# STM32L412C8T6 register map
File version: 1.0
Registers are 32-bit, access not given, reset 0x0 unless marked. A register's access mark holds for its fields unless they carry their own. Offsets are from the block's base; [hi:lo] are bit positions; {n}, {i} and the like mark numbered series; 'fields as' and 'values as' point back to an identical list.

## SDMMC
Base 0x40012800
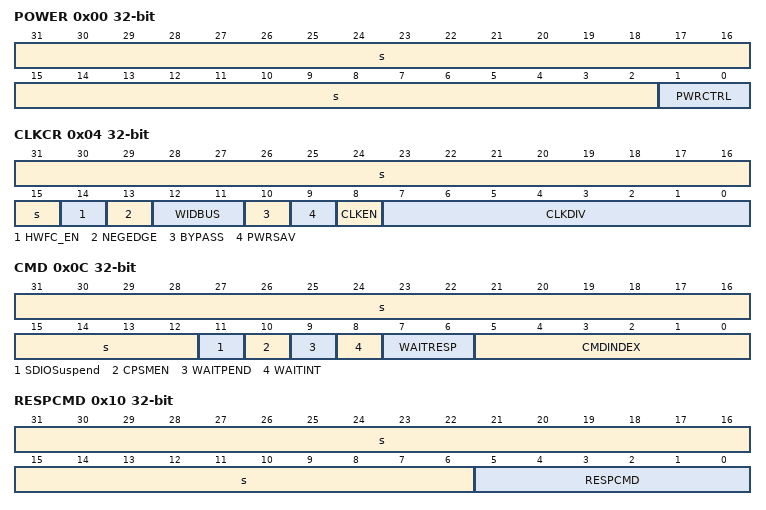
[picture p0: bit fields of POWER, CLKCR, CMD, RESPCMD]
0x00 POWER
  [31:2] s, [1:0] PWRCTRL
0x04 CLKCR
  [31:15] s, [14] HWFC_EN, [13] NEGEDGE, [12:11] WIDBUS, [10] BYPASS, [9] PWRSAV, [8] CLKEN, [7:0] CLKDIV
0x08 ARG
  [31:0] CMDARG
0x0C CMD
  [31:12] s, [11] SDIOSuspend, [10] CPSMEN, [9] WAITPEND, [8] WAITINT, [7:6] WAITRESP, [5:0] CMDINDEX
0x10 RESPCMD
  [31:6] s, [5:0] RESPCMD
{0x10+4i} RESP{i} (i=1..4)
  [31:0] CARDSTATUS{i}
0x24 DTIMER
  [31:0] DATATIME
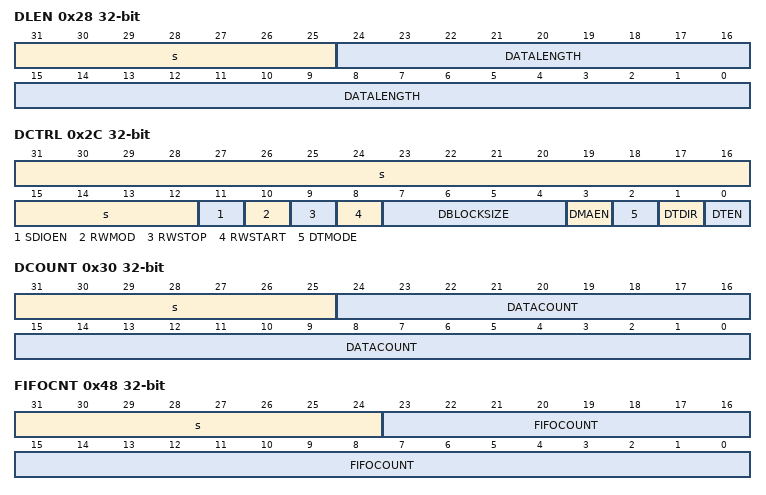
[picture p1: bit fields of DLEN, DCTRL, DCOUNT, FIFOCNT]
0x28 DLEN
  [31:25] s, [24:0] DATALENGTH
0x2C DCTRL
  [31:12] s, [11] SDIOEN, [10] RWMOD, [9] RWSTOP, [8] RWSTART, [7:4] DBLOCKSIZE, [3] DMAEN, [2] DTMODE, [1] DTDIR, [0] DTEN
0x30 DCOUNT
  [31:25] s, [24:0] DATACOUNT
0x34 STA
  [22] SDIOIT, [21] RXDAVL, [20] TXDAVL, [19] RXFIFOE, [18] TXFIFOE, [17] RXFIFOF, [16] TXFIFOF, [15] RXFIFOHF, [14] TXFIFOHE, [13] RXACT, [12] TXACT, [11] CMDACT, [10] DBCKEND, [31:9] s, [8] DATAEND, [7] CMDSENT, [6] CMDREND, [5] RXOVERR, [4] TXUNDERR, [3] DTIMEOUT, [2] CTIMEOUT, [1] DCRCFAIL, [0] CCRCFAIL
0x38 ICR
  [22] SDIOITC, [10] DBCKENDC, [31:9] s, [8] DATAENDC, [7] CMDSENTC, [6] CMDRENDC, [5] RXOVERRC, [4] TXUNDERRC, [3] DTIMEOUTC, [2] CTIMEOUTC, [1] DCRCFAILC, [0] CCRCFAILC
0x3C MASK
  [22] SDIOITIE, [21] RXDAVLIE, [20] TXDAVLIE, [19] RXFIFOEIE, [18] TXFIFOEIE, [17] RXFIFOFIE, [16] TXFIFOFIE, [15] RXFIFOHFIE, [14] TXFIFOHEIE, [13] RXACTIE, [12] TXACTIE, [11] CMDACTIE, [10] DBCKENDIE, [31:9] s, [8] DATAENDIE, [7] CMDSENTIE, [6] CMDRENDIE, [5] RXOVERRIE, [4] TXUNDERRIE, [3] DTIMEOUTIE, [2] CTIMEOUTIE, [1] DCRCFAILIE, [0] CCRCFAILIE
0x48 FIFOCNT
  [31:24] s, [23:0] FIFOCOUNT
0x80 FIFO
  [31:0] FIF0Data

## TIM15
Base 0x40014000
0x00 CR1
  [11] UIFREMAP, [9:8] CKD, [7] ARPE, [31:4] s, [3] OPM, [2] URS, [1] UDIS, [0] CEN
0x04 CR2
  [10] OIS2, [9] OIS1N, [8] OIS1, [7] TI1S, [6:4] MMS, [3] CCDS, [2] CCUS, [31:1] s, [0] CCPC
0x08 SMCR
  [7] MSM, [6:4] TS, [31:3] s, [16:0] SMS
0x0C DIER
  [14] TDE, [13] COMDE, [10] CC2DE, [9] CC1DE, [8] UDE, [7] BIE, [6] TIE, [5] COMIE, [31:3] s, [2] CC2IE, [1] CC1IE, [0] UIE
0x10 SR
  [10] CC2OF, [9] CC1OF, [7] BIF, [6] TIF, [5] COMIF, [31:3] s, [2] CC2IF, [1] CC1IF, [0] UIF
0x14 EGR
  [7] BG, [6] TG, [5] COMG, [31:3] s, [2] CC2G, [1] CC1G, [0] UG
0x18 CCMR1_OUT
  [24:12] OC2M, [11] OC2PE, [10] OC2FE, [9:8] CC2S, [31:7] s, [16:4] OC1M, [3] OC1PE, [2] OC1FE, [1:0] CC1S
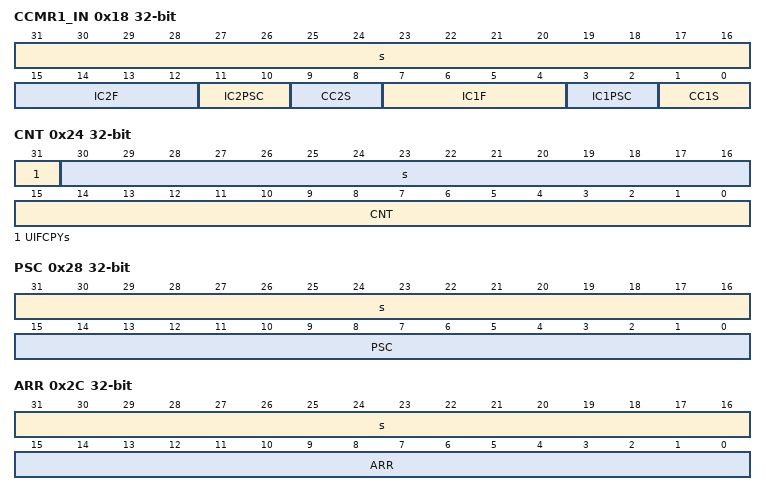
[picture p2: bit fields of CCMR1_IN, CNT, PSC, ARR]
0x18 CCMR1_IN
  [31:16] s, [15:12] IC2F, [11:10] IC2PSC, [9:8] CC2S, [7:4] IC1F, [3:2] IC1PSC, [1:0] CC1S
0x20 CCER
  [7] CC2NP, [31:6] s, [5] CC2P, [4] CC2E, [3] CC1NP, [2] CC1NE, [1] CC1P, [0] CC1E
0x24 CNT
  [31] UIFCPYs, [30:16] s, [15:0] CNT
0x28 PSC
  [31:16] s, [15:0] PSC
0x2C ARR
  [31:16] s, [15:0] ARR
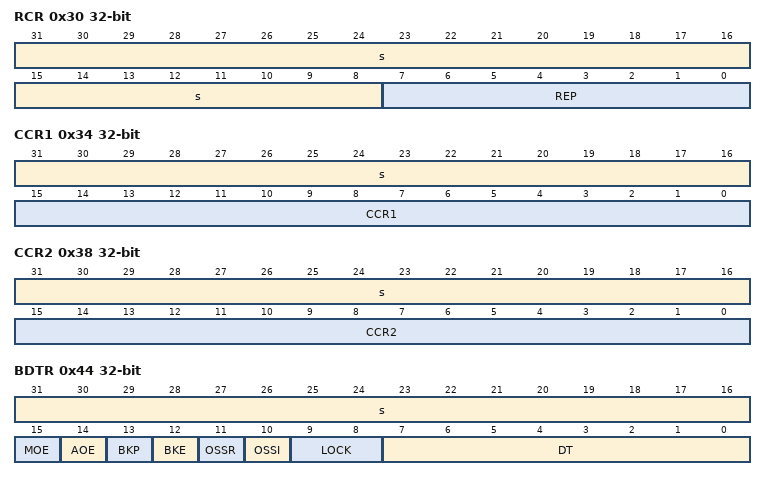
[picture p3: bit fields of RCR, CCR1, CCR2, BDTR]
0x30 RCR
  [31:8] s, [7:0] REP
0x34 CCR1
  [31:16] s, [15:0] CCR1
0x38 CCR2
  [31:16] s, [15:0] CCR2
0x44 BDTR
  [31:16] s, [15] MOE, [14] AOE, [13] BKP, [12] BKE, [11] OSSR, [10] OSSI, [9:8] LOCK, [7:0] DT
0x48 DCR
  [12:8] DBL, [31:5] s, [4:0] DBA
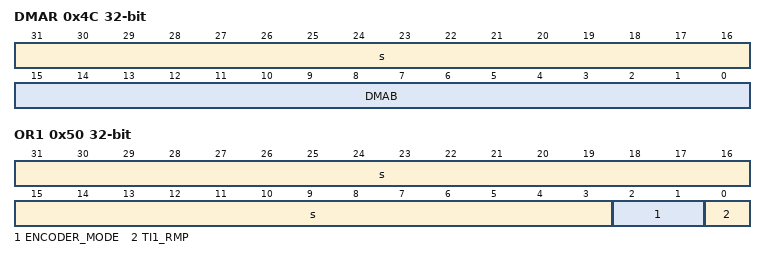
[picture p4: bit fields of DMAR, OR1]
0x4C DMAR
  [31:16] s, [15:0] DMAB
0x50 OR1
  [31:3] s, [2:1] ENCODER_MODE, [0] TI1_RMP
0x60 OR2
  [11] BKCMP2P, [10] BKCMP1P, [9] BKINP, [31:3] s, [2] BKCMP2E, [1] BKCMP1E, [0] BKINE

## TIM16
Base 0x40014400
Registers as TIM15, without SMCR, CCR2; these are added or differ:
0x04 CR2
  [9] OIS1N, [8] OIS1, [3] CCDS, [2] CCUS, [31:1] s, [0] CCPC
0x0C DIER
  [13] COMDE, [9] CC1DE, [8] UDE, [7] BIE, [5] COMIE, [31:2] s, [1] CC1IE, [0] UIE
0x10 SR
  [9] CC1OF, [7] BIF, [5] COMIF, [31:2] s, [1] CC1IF, [0] UIF
0x14 EGR
  [7] BG, [5] COMG, [31:2] s, [1] CC1G, [0] UG
0x18 CCMR1_OUT
  [31:7] s, [16:4] OC1M, [3] OC1PE, [2] OC1FE, [1:0] CC1S
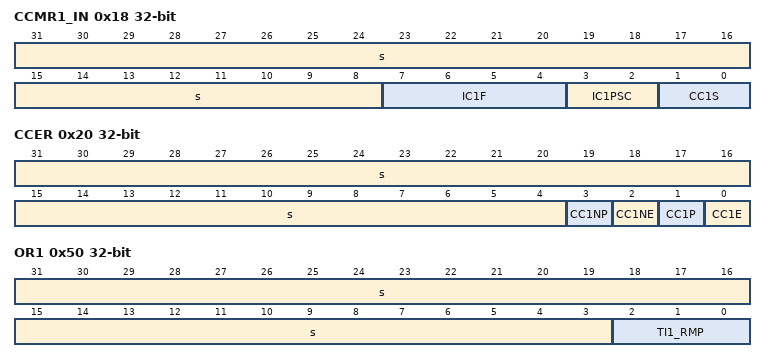
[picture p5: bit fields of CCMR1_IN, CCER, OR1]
0x18 CCMR1_IN
  [31:8] s, [7:4] IC1F, [3:2] IC1PSC, [1:0] CC1S
0x20 CCER
  [31:4] s, [3] CC1NP, [2] CC1NE, [1] CC1P, [0] CC1E
0x50 OR1
  [31:3] s, [2:0] TI1_RMP

## SAI1
Base 0x40015400
0x04 CR1A
  [23:20] MCKDIV, [19] NODIV, [17] DMAEN, [16] SAIEN, [13] OUTDRIV, [12] MONO, [11:10] SYNCEN, [9] CKSTR, [8] LSBFIRST, [7:5] DS, [31:4] s, [3:2] PRTCFG, [1:0] MODE
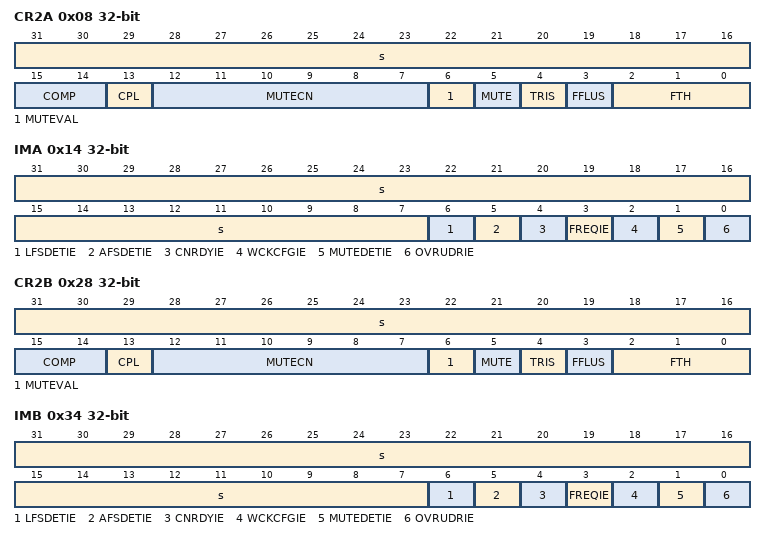
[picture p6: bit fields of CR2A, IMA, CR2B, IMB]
0x08 CR2A
  [31:16] s, [15:14] COMP, [13] CPL, [12:7] MUTECN, [6] MUTEVAL, [5] MUTE, [4] TRIS, [3] FFLUS, [2:0] FTH
0x0C FRCRA
  [18] FSOFF, [17] FSPOL, [16] FSDEF, [31:15] s, [14:8] FSALL, [7:0] FRL
0x10 SLOTRA
  [31:16] SLOTEN, [11:8] NBSLOT, [7:6] SLOTSZ}, [15:5] s, [4:0] FBOFF
0x14 IMA
  [31:7] s, [6] LFSDETIE, [5] AFSDETIE, [4] CNRDYIE, [3] FREQIE, [2] WCKCFGIE, [1] MUTEDETIE, [0] OVRUDRIE
0x18 SRA
  [18:16] FLVL, [31:7] s, [6] LFSDET, [5] AFSDET, [4] CNRDY, [3] FREQ, [2] WCKCFG, [1] MUTEDET, [0] OVRUDR
0x1C CLRFRA
  [6] CLFSDET, [5] CAFSDET, [4] CCNRDY, [31:3] s, [2] CWCKCFG, [1] CMUTEDET, [0] COVRUDR
0x20 DRA
  [31:0] DATA
0x24 CR1B
  fields as CR1A
0x28 CR2B
  fields as CR2A
0x2C FRCRB
  fields as FRCRA
0x30 SLOTRB
  [31:16] SLOTEN, [11:8] NBSLOT, [7:6] SLOTSZ}, [15:5] s, [4:0] FBOFF
0x34 IMB
  fields as IMA
0x38 SRB
  fields as SRA
0x3C CLRFRB
  fields as CLRFRA
0x40 DRB
  [31:0] DATA
